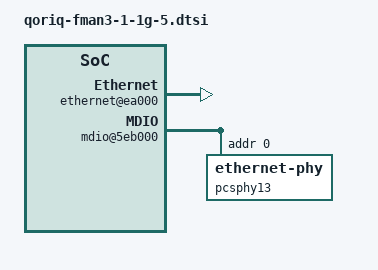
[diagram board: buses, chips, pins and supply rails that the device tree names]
// SPDX-License-Identifier: (GPL-2.0+ OR BSD-3-Clause)
/*
 * QorIQ FMan v3 1g port #5 device tree stub [ controller @ offset 0x500000 ]
 *
 * Copyright 2012 - 2015 Freescale Semiconductor Inc.
 * Copyright 2020 NXP
 *
 */

fman@500000 {
	fman1_rx_0x0d: port@8d000 {
		cell-index = <0xd>;
		compatible = "fsl,fman-v3-port-rx";
		reg = <0x8d000 0x1000>;
	};

	fman1_tx_0x2d: port@ad000 {
		cell-index = <0x2d>;
		compatible = "fsl,fman-v3-port-tx";
		reg = <0xad000 0x1000>;
	};

	ethernet@ea000 {
		cell-index = <5>;
		compatible = "fsl,fman-memac";
		reg = <0xea000 0x1000>;
		fsl,fman-ports = <&fman1_rx_0x0d &fman1_tx_0x2d>;
		ptp-timer = <&ptp_timer1>;
		pcsphy-handle = <&pcsphy13>;
	};

	mdio@5eb000 {
		#address-cells = <1>;
		#size-cells = <0>;
		compatible = "fsl,fman-memac-mdio", "fsl,fman-xmdio";
		reg = <0xeb000 0x1000>;
		fsl,erratum-a011043; /* must ignore read errors */

		pcsphy13: ethernet-phy@0 {
			reg = <0x0>;
		};
	};
};
